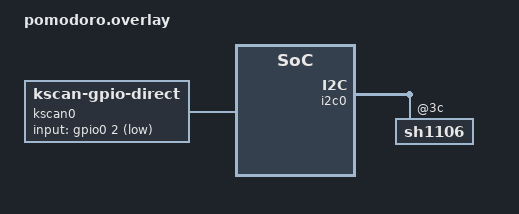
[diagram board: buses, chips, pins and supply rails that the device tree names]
/ {
    chosen {
        zmk,kscan = &kscan0;
        zmk,display = &oled;
    };

    kscan0: kscan {
        compatible = "zmk,kscan-gpio-direct";
        input-gpios = <&gpio0 2 (GPIO_ACTIVE_LOW | GPIO_PULL_UP)>;
    };

    oled: sh1106@3c {
        compatible = "sinowealth,sh1106";
        reg = <0x3c>;
        width = <128>;
        height = <64>;
        segment-offset = <2>;
        page-offset = <0>;
        display-offset = <0>;
        multiplex-ratio = <63>;
        segment-remap;
        com-invdir;
        prechargep = <0x22>;
    };
};

&i2c0 {
    status = "okay";
    
    sh1106@3c {
        status = "okay";
    };
};
